AUTOSAR XML (schema 4-2-2)
package /ASW_CORE4
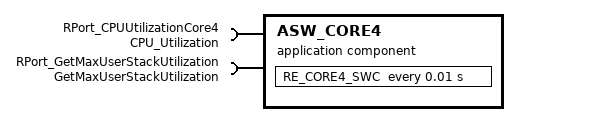
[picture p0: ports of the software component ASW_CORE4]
  application sw component type ASW_CORE4
    require port RPort_CPUUtilizationCore4: required-interface=CPU_Utilization
    require port RPort_GetMaxUserStackUtilization: required-interface=GetMaxUserStackUtilization
    behavior SwcInternalBehavior
      timing event TimingEvent_0: start-on-event=RE_CORE4_SWC, period=0.01
      runnable RE_CORE4_SWC: symbol=RE_CORE4_SWC_func
        sync call SynchronousServerCallPoint_0: operation=RPort_CPUUtilizationCore4.CPU_Utilization
        sync call SynchronousServerCallPoint_1: operation=RPort_GetMaxUserStackUtilization.GetMaxUserStackUtilization
